# platform_designer_hps_system_hps_0_hps register map
Vendor: default_vendor.com; File version: 0.0
Registers are 32-bit, read-write, reset 0x0 unless marked. A register's access mark holds for its fields unless they carry their own. Offsets are from the block's base; [hi:lo] are bit positions; {n}, {i} and the like mark numbered series; 'fields as' and 'values as' point back to an identical list.

## acpidmap — Registers in the ACP ID Mapper module
Base 0xFF707000
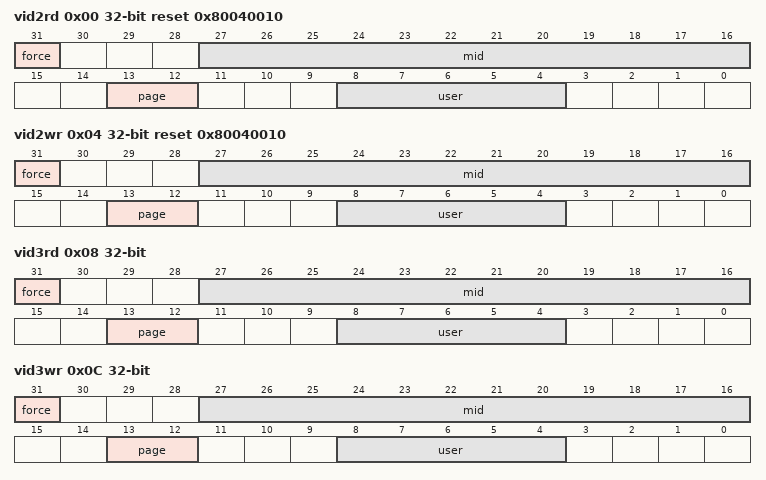
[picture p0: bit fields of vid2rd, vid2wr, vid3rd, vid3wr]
0x00 vid2rd reset 0x80040010 — The Read AXI Master Mapping Register contains the USER, ADDR page, and ID signals mapping values for particular transaction with 12-bit ID which locks the fixed 3-bit virtual ID.
  [31] force — Set to 1 to force the mapping between the 12-bit ID and 3-bit virtual ID N. Set to 0 to allow the 3-bit ID N to be dynamically allocated.
  [27:16] mid — The 12-bit ID of the master to remap to 3-bit virtual ID N, where N is the 3-bit ID to use.
  [13:12] page — ARADDR remap to 1st, 2nd, 3rd, or 4th 1GB memory region.
  [8:4] user — This value is propagated to SCU as ARUSERS.
0x04 vid2wr reset 0x80040010 — The Write AXI Master Mapping Register contains the USER, ADDR page, and ID signals mapping values for particular transaction with 12-bit ID which locks the fixed 3-bit virtual ID.
  [31] force — Set to 1 to force the mapping between the 12-bit ID and 3-bit virtual ID N. Set to 0 to allow the 3-bit ID N to be dynamically allocated.
  [27:16] mid — The 12-bit ID of the master to remap to 3-bit virtual ID N, where N is the 3-bit ID to use.
  [13:12] page — AWADDR remap to 1st, 2nd, 3rd, or 4th 1GB memory region.
  [8:4] user — This value is propagated to SCU as AWUSERS.
0x08 vid3rd — The Read AXI Master Mapping Register contains the USER, ADDR page, and ID signals mapping values for particular transaction with 12-bit ID which locks the fixed 3-bit virtual ID.
  fields as vid2rd
0x0C vid3wr — The Write AXI Master Mapping Register contains the USER, ADDR page, and ID signals mapping values for particular transaction with 12-bit ID which locks the fixed 3-bit virtual ID.
  fields as vid2wr
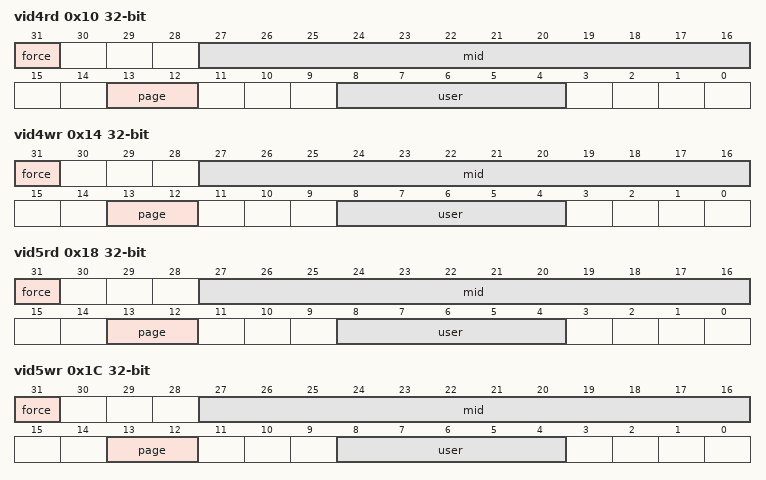
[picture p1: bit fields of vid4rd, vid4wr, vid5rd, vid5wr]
0x10 vid4rd — The Read AXI Master Mapping Register contains the USER, ADDR page, and ID signals mapping values for particular transaction with 12-bit ID which locks the fixed 3-bit virtual ID.
  fields as vid2rd
0x14 vid4wr — The Write AXI Master Mapping Register contains the USER, ADDR page, and ID signals mapping values for particular transaction with 12-bit ID which locks the fixed 3-bit virtual ID.
  fields as vid2wr
0x18 vid5rd — The Read AXI Master Mapping Register contains the USER, ADDR page, and ID signals mapping values for particular transaction with 12-bit ID which locks the fixed 3-bit virtual ID.
  fields as vid2rd
0x1C vid5wr — The Write AXI Master Mapping Register contains the USER, ADDR page, and ID signals mapping values for particular transaction with 12-bit ID which locks the fixed 3-bit virtual ID.
  fields as vid2wr
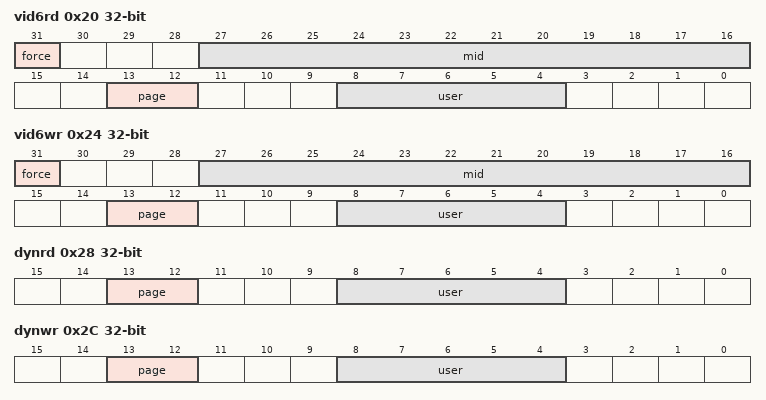
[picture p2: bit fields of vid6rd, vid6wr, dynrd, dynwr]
0x20 vid6rd — The Read AXI Master Mapping Register contains the USER, ADDR page, and ID signals mapping values for particular transaction with 12-bit ID which locks the fixed 3-bit virtual ID.
  fields as vid2rd
0x24 vid6wr — The Write AXI Master Mapping Register contains the USER, ADDR page, and ID signals mapping values for particular transaction with 12-bit ID which locks the fixed 3-bit virtual ID.
  fields as vid2wr
0x28 dynrd — The Read AXI Master Mapping Register contains the USER, and ADDR page signals mapping values for transaction that dynamically remapped to one of the available 3-bit virtual IDs.
  [13:12] page — ARADDR remap to 1st, 2nd, 3rd, or 4th 1GB memory region.
  [8:4] user — This value is propagated to SCU as ARUSERS.
0x2C dynwr — The Write AXI Master Mapping Register contains the USER, and ADDR page signals mapping values for transaction that dynamically remapped to one of the available 3-bit virtual IDs.
  [13:12] page — AWADDR remap to 1st, 2nd, 3rd, or 4th 1GB memory region.
  [8:4] user — This value is propagated to SCU as AWUSERS.
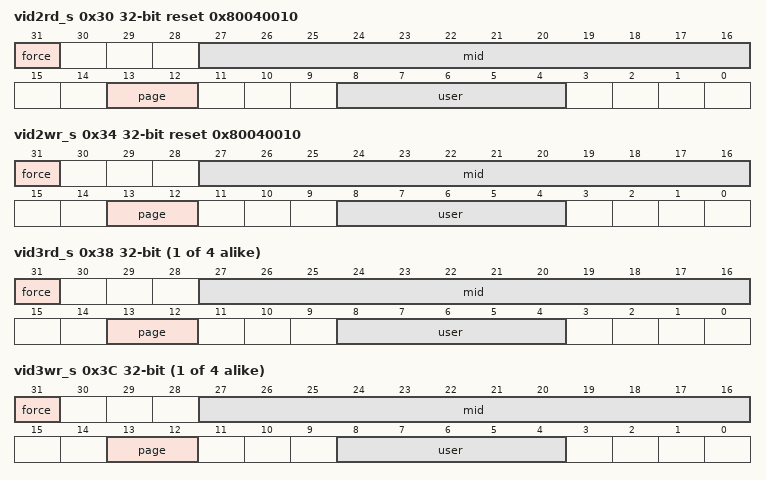
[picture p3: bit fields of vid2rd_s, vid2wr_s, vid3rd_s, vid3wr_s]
0x30 vid2rd_s ro reset 0x80040010 (reset mask 0xFFFFCFFF) — The Read AXI Master Mapping Status Register contains the configured USER, ADDR page, and ID signals mapping values for particular transaction with 12-bit ID which locks the fixed 3-bit virtual ID.
  fields as vid2rd
0x34 vid2wr_s ro reset 0x80040010 (reset mask 0xFFFFCFFF) — The Write AXI Master Mapping Status Register contains the configured USER, ADDR page, and ID signals mapping values for particular transaction with 12-bit ID which locks the fixed 3-bit virtual ID.
  fields as vid2wr
{0x20+8i} vid{i}rd_s ro (reset mask 0x7000CE0F) (i=3..6) — The Read AXI Master Mapping Status Register contains the configured USER, ADDR page, and ID signals mapping values for particular transaction with 12-bit ID which locks the fixed 3-bit virtual ID.
  fields as vid2rd
{0x24+8i} vid{i}wr_s ro (reset mask 0x7000CE0F) (i=3..6) — The Write AXI Master Mapping Status Register contains the configured USER, ADDR page, and ID signals mapping values for particular transaction with 12-bit ID which locks the fixed 3-bit virtual ID.
  fields as vid2wr
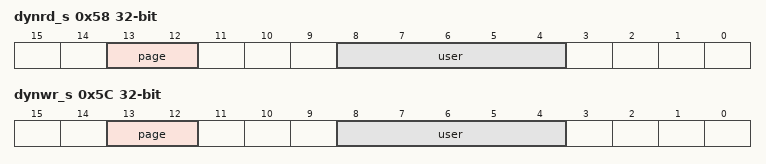
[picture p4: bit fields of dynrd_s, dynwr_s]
0x58 dynrd_s ro (reset mask 0xFFFFCE0F) — The Read AXI Master Mapping Status Register contains the configured USER, and ADDR page signals mapping values for transaction that dynamically remapped to one of the available 3-bit virtual IDs.
  fields as dynrd
0x5C dynwr_s ro (reset mask 0xFFFFCE0F) — The Write AXI Master Mapping Status Register contains the configured USER, and ADDR page signals mapping values for transaction that dynamically remapped to one of the available 3-bit virtual IDs.
  fields as dynwr
